# PIC32CM3204PL10028 register map
Vendor: Microchip Technology; Series: PIC32CMPL10; File version: 0
CPU: CM0+ r0p0, little endian, no MPU, no FPU, VTOR, 2 interrupt priority bits, 15 interrupts
Registers are 32-bit, read-write, reset 0x0 unless marked. A register's access mark holds for its fields unless they carry their own. Offsets are from the block's base; [hi:lo] are bit positions; {n}, {i} and the like mark numbered series; 'fields as' and 'values as' point back to an identical list.

## EIC — External Interrupt Controller
Base 0x40002800
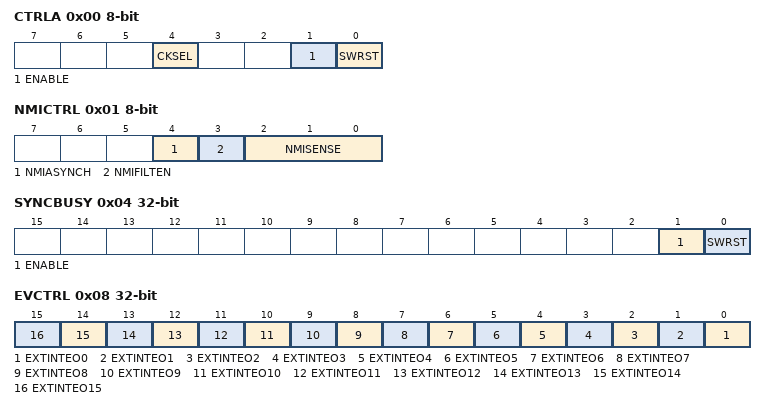
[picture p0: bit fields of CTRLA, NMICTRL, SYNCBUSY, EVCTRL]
0x00 CTRLA 8-bit — Control A
  [4] CKSEL — Clock Selection
    0=GCLK_EIC (The EIC is clocked by GCLK_EIC); 1=CLK_OSC32K (The EIC is clocked by CLK_OSC32K)
  [1] ENABLE
  [0] SWRST — Software Reset
0x01 NMICTRL 8-bit — Non-Maskable Interrupt Control
  [4] NMIASYNCH — NMI Asynchronous Edge Detection Mode
  [3] NMIFILTEN — Non-Maskable Interrupt Filter Enable
  [2:0] NMISENSE — Non-Maskable Interrupt Sense Configuration
    0=NONE (No detection); 1=RISE (Rising-edge detection); 2=FALL (Falling-edge detection); 3=BOTH (Both-edge detection); 4=HIGH (High-level detection); 5=LOW (Low-level detection)
0x02 NMIFLAG 16-bit write-1-clears — Non-Maskable Interrupt Flag Status and Clear
  [0] NMI — Non-Maskable Interrupt
0x04 SYNCBUSY ro — Synchronization Busy
  [1] ENABLE — Enable Synchronization Busy Status
  [0] SWRST — Software Reset Synchronization Busy Status
0x08 EVCTRL — Event Control
  [n] EXTINTEO{n} (n=0..15) — External Interrupt Event Output Enable {n}
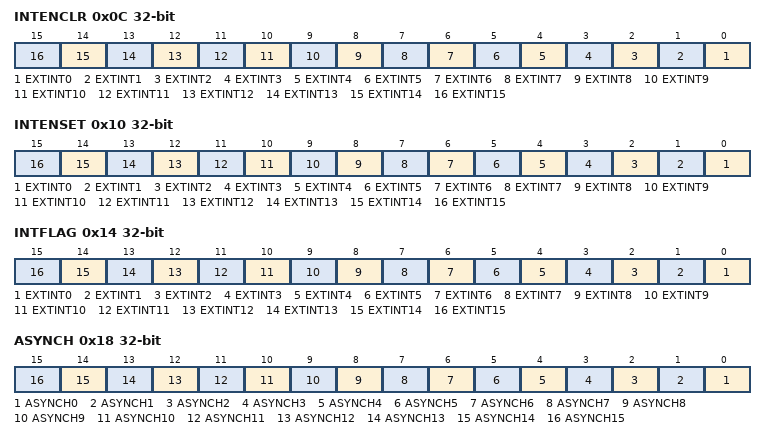
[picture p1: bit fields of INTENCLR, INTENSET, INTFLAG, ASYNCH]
0x0C INTENCLR write-1-clears — Interrupt Enable Clear
  [n] EXTINT{n} (n=0..15) — External Interrupt Enable {n}
0x10 INTENSET write-1-sets — Interrupt Enable Set
  [n] EXTINT{n} (n=0..15) — External Interrupt Enable {n}
0x14 INTFLAG write-1-clears — Interrupt Flag Status and Clear
  [n] EXTINT{n} (n=0..15) — External Interrupt {n}
0x18 ASYNCH — External Interrupt Asynchronous Mode
  [n] ASYNCH{n} (n=0..15) — Asynchronous Edge Detection Mode {n}
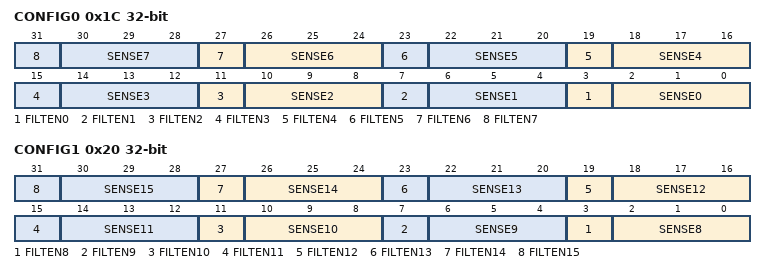
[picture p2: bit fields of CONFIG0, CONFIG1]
0x1C CONFIG0 — External Interrupt Sense Configuration 0
  [4n+3] FILTEN{n} (n=0..7) — Filter Enable {n}
  [4n+2:4n] SENSE{n} (n=0..7) — Input Sense Configuration {n}
    values as NMICTRL.NMISENSE
0x20 CONFIG1 — External Interrupt Sense Configuration 1
  [4n-29] FILTEN{n} (n=8..15) — Filter Enable {n}
  [4n-30:4n-32] SENSE{n} (n=8..15) — Input Sense Configuration {n}
    values as NMICTRL.NMISENSE

## EVSYS — Event System
Base 0x42000000
0x00 CTRLA 8-bit wo — Control A
  [0] SWRST — Software Reset
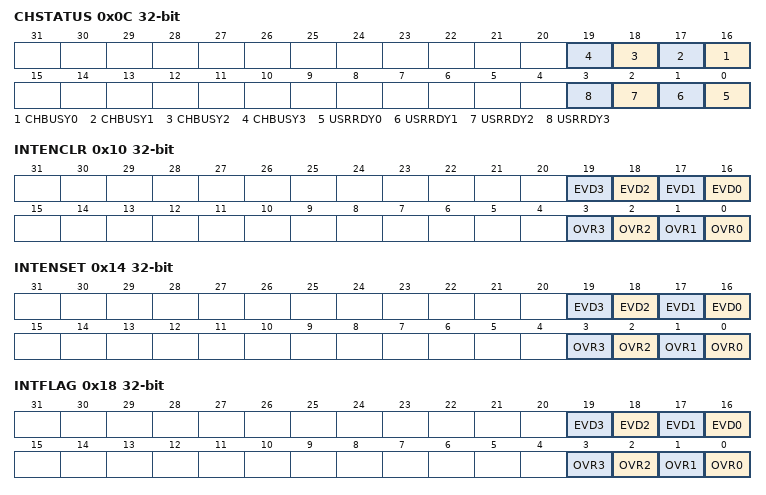
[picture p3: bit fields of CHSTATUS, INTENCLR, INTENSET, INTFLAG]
0x0C CHSTATUS ro — Channel Status
  [n+16] CHBUSY{n} (n=0..3) — Channel {n} Busy
  [n] USRRDY{n} (n=0..3) — Users Ready on Channel {n}
0x10 INTENCLR write-1-clears — Interrupt Enable Clear
  [n+16] EVD{n} (n=0..3) — Event Detected Channel {n} Interrupt Enable
  [n] OVR{n} (n=0..3) — Overrun Channel {n} Interrupt Enable
0x14 INTENSET write-1-sets — Interrupt Enable Set
  fields as INTENCLR
0x18 INTFLAG write-1-clears — Interrupt Flag Status and Clear
  [n+16] EVD{n} (n=0..3) — Event Detected Channel {n}
  [n] OVR{n} (n=0..3) — Overrun Channel {n}
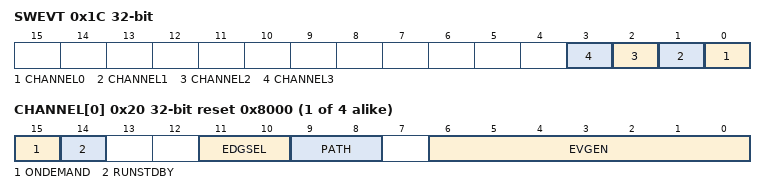
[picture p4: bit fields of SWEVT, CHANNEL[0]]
0x1C SWEVT wo — Software Event
  [n] CHANNEL{n} (n=0..3) — Channel {n} Software Selection
{0x20+4i} CHANNEL[{i}] (i=0..3) reset 0x8000 — Channel # Control
  [15] ONDEMAND — Generic Clock On Demand
  [14] RUNSTDBY — Run in Standby
  [11:10] EDGSEL — Edge Detection Selection
    0=NO_EVT_OUTPUT (No event output when using the resynchronized or synchronous path); 1=RISING_EDGE (Event detection occurs only on the rising edge of the signal from the event generator); 2=FALLING_EDGE (Event detection occurs only on the falling edge of the signal from the event generator); 3=BOTH_EDGES (Event detection occurs on both the rising and falling edges of the signal from the event generator)
  [9:8] PATH — Path Selection
    0=SYNCHRONOUS (Synchronous path); 1=RESYNCHRONIZED (Resynchronized path); 2=ASYNCHRONOUS (Asynchronous path)
  [6:0] EVGEN — Event Generator
{0x80+4i} USER[{i}] (i=0..22) — User # Channel Selection
  [4:0] CHANNEL — Channel Event Selection
    0=OFF (The Event System user is not connected to any channel); {v}=The Event System user is connected to Channel {v-1} (v=1..4)

## Notices in the file
Copyright (c) 2026 Microchip Technology Inc.
SPDX-License-Identifier: Apache-2.0
Licensed under the Apache License, Version 2.0 (the "License");
you may not use this file except in compliance with the License.
You may obtain a copy of the License at
http://www.apache.org/licenses/LICENSE-2.0
Unless required by applicable law or agreed to in writing, software
distributed under the License is distributed on an "AS IS" BASIS,
WITHOUT WARRANTIES OR CONDITIONS OF ANY KIND, either express or implied.
See the License for the specific language governing permissions and
limitations under the License.
